AUTOSAR XML (schema 00044)
package /E40_Platform_System_SystemPackage/Components
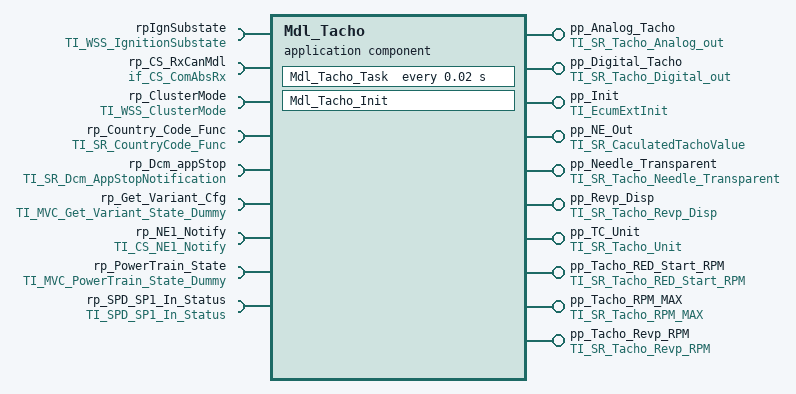
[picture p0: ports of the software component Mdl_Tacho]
  application sw component type Mdl_Tacho
    10 x provide port:
      pp_Analog_Tacho: nonqueued-sender-com-spec{data-element=Analog_Tacho, init-value=constant-reference=Mdl_TachoAnalog_TachoValue0}, provided-interface=TI_SR_Tacho_Analog_out
      pp_Digital_Tacho: nonqueued-sender-com-spec{data-element=Digital_Tacho, init-value=constant-reference=Mdl_TachoDigital_TachoValue0}, provided-interface=TI_SR_Tacho_Digital_out
      pp_Init: server-com-spec{operation=Init, queue-length=1}, provided-interface=TI_EcumExtInit
      pp_NE_Out: nonqueued-sender-com-spec{data-element=CalTachoValue, init-value=constant-reference=Mdl_TachoCalTachoValueValue0}, provided-interface=TI_SR_CaculatedTachoValue
      pp_Needle_Transparent: nonqueued-sender-com-spec{data-element=Needle_TR, init-value=constant-reference=Mdl_TachoNeedle_TRValue0}, provided-interface=TI_SR_Tacho_Needle_Transparent
      pp_Revp_Disp: nonqueued-sender-com-spec{data-element=REVP_DISP, init-value=constant-reference=Mdl_TachoREVP_DISPValue0}, provided-interface=TI_SR_Tacho_Revp_Disp
      pp_TC_Unit: nonqueued-sender-com-spec{data-element=Digital_TachoUnit, init-value=constant-reference=Mdl_TachoDigital_TachoUnitValue0}, provided-interface=TI_SR_Tacho_Unit
      pp_Tacho_RED_Start_RPM: nonqueued-sender-com-spec{data-element=RED_Start_RPM, init-value=constant-reference=Mdl_TachoRED_Start_RPMValue0}, provided-interface=TI_SR_Tacho_RED_Start_RPM
      pp_Tacho_RPM_MAX: nonqueued-sender-com-spec{data-element=REVP_RPM_MAX, init-value=constant-reference=Mdl_TachoREVP_RPM_MAXValue0}, provided-interface=TI_SR_Tacho_RPM_MAX
      pp_Tacho_Revp_RPM: nonqueued-sender-com-spec{data-element=REVP_RPM, init-value=constant-reference=Mdl_TachoREVP_RPMValue0}, provided-interface=TI_SR_Tacho_Revp_RPM
    9 x require port:
      rpIgnSubstate: nonqueued-receiver-com-spec{data-element=IgnitionSubstate, init-value=constant-reference=Mdl_TachoIgnitionSubstateValue0}, required-interface=TI_WSS_IgnitionSubstate
      rp_CS_RxCanMdl: required-interface=if_CS_ComAbsRx
        required-com-specs:
          RxCan_GetSignalValue
          RxCan_GetSignalValueU8Arr
          RxCan_SetSignalInitValue
          RxCan_SetSignalInitValueU8Arr
          RxCan_SignalClearJustRcvdStatus
          RxCan_SignalGetJustRcvdStatus
          RxCan_SignalInvalidProcessingControl
          RxCan_SignalMissingProcessingControl
          RxCan_SignalNRProcessingControl
      rp_ClusterMode: nonqueued-receiver-com-spec{data-element=WSSCurrentClusterMode, init-value=constant-reference=Mdl_TachoWSSCurrentClusterModeValue0}, required-interface=TI_WSS_ClusterMode
      rp_Country_Code_Func: nonqueued-receiver-com-spec{data-element=CountryCode_Func, init-value=constant-reference=Mdl_TachoCountryCode_FuncValue0}, required-interface=TI_SR_CountryCode_Func
      rp_Dcm_appStop: nonqueued-receiver-com-spec{data-element=AppId, init-value=constant-reference=Mdl_TachoAppIdValue0}, required-interface=TI_SR_Dcm_AppStopNotification
      rp_Get_Variant_Cfg: client-com-spec=Get_Variant_Config_State, required-interface=TI_MVC_Get_Variant_State_Dummy
      rp_NE1_Notify: client-com-spec=NE1_Recieve_Notify_Value, required-interface=TI_CS_NE1_Notify
      rp_PowerTrain_State: nonqueued-receiver-com-spec{data-element=PowerTrain_Flag, init-value=constant-reference=Mdl_TachoPowerTrain_FlagValue0}, required-interface=TI_MVC_PowerTrain_State_Dummy
      rp_SPD_SP1_In_Status: nonqueued-receiver-com-spec{data-element=SP1_In_Status, init-value=constant-reference=Mdl_TachoSP1_In_StatusValue0}, required-interface=TI_SPD_SP1_In_Status
    behavior IB_Mdl_Tacho
      operation invoked event OIE_pp_Init_Mdl_Tacho_InitTrigByInit: start-on-event=Mdl_Tacho_Init, operation=pp_Init.Init
      timing event TEMdl_Tacho_Task: start-on-event=Mdl_Tacho_Task, period=0.02
      port-api-options:
        enable-take-address=false, indirect-api=false, port=pp_Analog_Tacho
        enable-take-address=false, indirect-api=false, port=pp_Digital_Tacho
        enable-take-address=false, indirect-api=false, port=pp_Init
        enable-take-address=false, indirect-api=false, port=pp_NE_Out
        enable-take-address=false, indirect-api=false, port=pp_Needle_Transparent
        enable-take-address=false, indirect-api=false, port=pp_Revp_Disp
        enable-take-address=false, indirect-api=false, port=pp_TC_Unit
        enable-take-address=false, indirect-api=false, port=pp_Tacho_RED_Start_RPM
        enable-take-address=false, indirect-api=false, port=pp_Tacho_RPM_MAX
        enable-take-address=false, indirect-api=false, port=pp_Tacho_Revp_RPM
        enable-take-address=false, indirect-api=false, port=rpIgnSubstate
        enable-take-address=false, indirect-api=false, port=rp_CS_RxCanMdl
        enable-take-address=false, indirect-api=false, port=rp_ClusterMode
        enable-take-address=false, indirect-api=false, port=rp_Country_Code_Func
        enable-take-address=false, indirect-api=false, port=rp_Dcm_appStop
        enable-take-address=false, indirect-api=false, port=rp_Get_Variant_Cfg
        enable-take-address=false, indirect-api=false, port=rp_NE1_Notify
        enable-take-address=false, indirect-api=false, port=rp_PowerTrain_State
        enable-take-address=false, indirect-api=false, port=rp_SPD_SP1_In_Status
      runnable Mdl_Tacho_Init: can-be-invoked-concurrently=true
      runnable Mdl_Tacho_Task: can-be-invoked-concurrently=true
        data-receive-point-by-arguments:
          6 x access:
            DRA_rpIgnSubstate_IgnitionSubstate: accessed-variable=rpIgnSubstate.IgnitionSubstate
            DRA_rp_ClusterMode_WSSCurrentClusterMode: accessed-variable=rp_ClusterMode.WSSCurrentClusterMode
            DRA_rp_Country_Code_Func_CountryCode_Func: accessed-variable=rp_Country_Code_Func.CountryCode_Func
            DRA_rp_Dcm_appStop_AppId: accessed-variable=rp_Dcm_appStop.AppId
            DRA_rp_PowerTrain_State_PowerTrain_Flag: accessed-variable=rp_PowerTrain_State.PowerTrain_Flag
            DRA_rp_SPD_SP1_In_Status_SP1_In_Status: accessed-variable=rp_SPD_SP1_In_Status.SP1_In_Status
        data-send-points:
          9 x access:
            DWA_pp_Analog_Tacho_Analog_Tacho: accessed-variable=pp_Analog_Tacho.Analog_Tacho
            DWA_pp_Digital_Tacho_Digital_Tacho: accessed-variable=pp_Digital_Tacho.Digital_Tacho
            DWA_pp_NE_Out_CalTachoValue: accessed-variable=pp_NE_Out.CalTachoValue
            DWA_pp_Needle_Transparent_Needle_TR: accessed-variable=pp_Needle_Transparent.Needle_TR
            DWA_pp_Revp_Disp_REVP_DISP: accessed-variable=pp_Revp_Disp.REVP_DISP
            DWA_pp_TC_Unit_Digital_TachoUnit: accessed-variable=pp_TC_Unit.Digital_TachoUnit
            DWA_pp_Tacho_RED_Start_RPM_RED_Start_RPM: accessed-variable=pp_Tacho_RED_Start_RPM.RED_Start_RPM
            DWA_pp_Tacho_RPM_MAX_REVP_RPM_MAX: accessed-variable=pp_Tacho_RPM_MAX.REVP_RPM_MAX
            DWA_pp_Tacho_Revp_RPM_REVP_RPM: accessed-variable=pp_Tacho_Revp_RPM.REVP_RPM
        11 x sync call:
          OA_rp_CS_RxCanMdl_RxCan_GetSignalValueU8Arr: operation=rp_CS_RxCanMdl.RxCan_GetSignalValueU8Arr
          OA_rp_CS_RxCanMdl_RxCan_SetSignalInitValue: operation=rp_CS_RxCanMdl.RxCan_SetSignalInitValue
          OA_rp_CS_RxCanMdl_RxCan_SetSignalInitValueU8Arr: operation=rp_CS_RxCanMdl.RxCan_SetSignalInitValueU8Arr
          OA_rp_CS_RxCanMdl_RxCan_SignalInvalidProcessingControl: operation=rp_CS_RxCanMdl.RxCan_SignalInvalidProcessingControl
          OA_rp_CS_RxCanMdl_RxCan_SignalMissingProcessingControl: operation=rp_CS_RxCanMdl.RxCan_SignalMissingProcessingControl
          OA_rp_CS_RxCanMdl_RxCan_SignalNRProcessingControl: operation=rp_CS_RxCanMdl.RxCan_SignalNRProcessingControl
          OA_rp_CS_RxCanMdl_RxCan_SignalGetJustRcvdStatus: operation=rp_CS_RxCanMdl.RxCan_SignalGetJustRcvdStatus
          OA_rp_CS_RxCanMdl_RxCan_SignalClearJustRcvdStatus: operation=rp_CS_RxCanMdl.RxCan_SignalClearJustRcvdStatus
          OA_rp_CS_RxCanMdl_RxCan_GetSignalValue: operation=rp_CS_RxCanMdl.RxCan_GetSignalValue
          OA_rp_Get_Variant_Cfg_Get_Variant_Config_State: operation=rp_Get_Variant_Cfg.Get_Variant_Config_State
          OA_rp_NE1_Notify_NE1_Recieve_Notify_Value: operation=rp_NE1_Notify.NE1_Recieve_Notify_Value
  swc implementation IMPL_Mdl_Tacho: behavior=IB_Mdl_Tacho
